VERSION ""

NS_ :

BS_:

BU_: Tester

BO_ 3 Test: 8 Tester
 SG_ TestSig : 0|8@1- (1,0) [0|0] ""  Tester

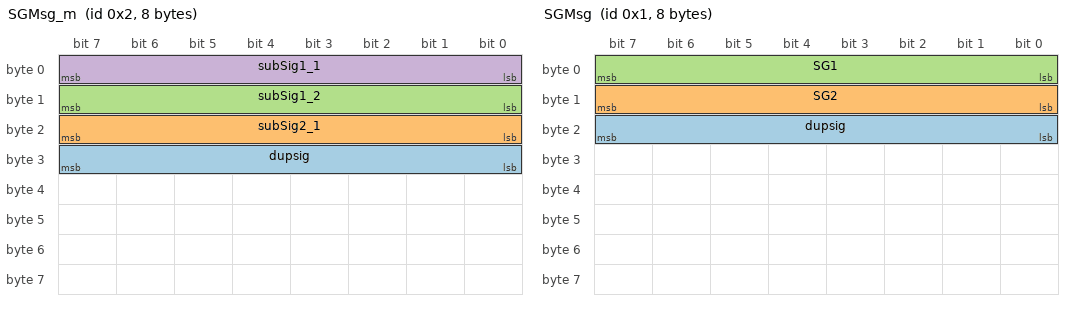
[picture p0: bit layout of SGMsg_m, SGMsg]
BO_ 2 SGMsg_m: 8 Vector__XXX
 SG_ dupsig : 24|8@1- (1,0) [0|0] "" Vector__XXX
 SG_ subSig2_1 : 16|8@1- (1,0) [0|0] "" Vector__XXX
 SG_ subSig1_2 : 8|8@1- (1,0) [0|0] "" Vector__XXX
 SG_ subSig1_1 : 0|8@1- (1,0) [0|0] "" Vector__XXX

BO_ 1 SGMsg: 8 Vector__XXX
 SG_ dupsig : 16|8@1- (1,0) [0|0] "" Vector__XXX
 SG_ SG2 : 8|8@1- (1,0) [0|0] "" Vector__XXX
 SG_ SG1 : 0|8@1- (1,0) [0|0] "" Vector__XXX

BO_ 0 NormalMsg: 8 Vector__XXX
 SG_ Sig_2 : 8|8@1- (1,0) [0|0] "" Vector__XXX
 SG_ Sig_1 : 0|8@1- (1,0) [0|0] "" Vector__XXX

BA_DEF_  "BusType" STRING ;
BA_DEF_DEF_  "BusType" "CAN";

SIG_GROUP_ 2 Sub2 1 : dupsig subSig2_1;
SIG_GROUP_ 2 sub1 1 : dupsig subSig1_2 subSig1_1;
SIG_GROUP_ 1 New_Signal_Group_46 1 : SG2 SG1;
